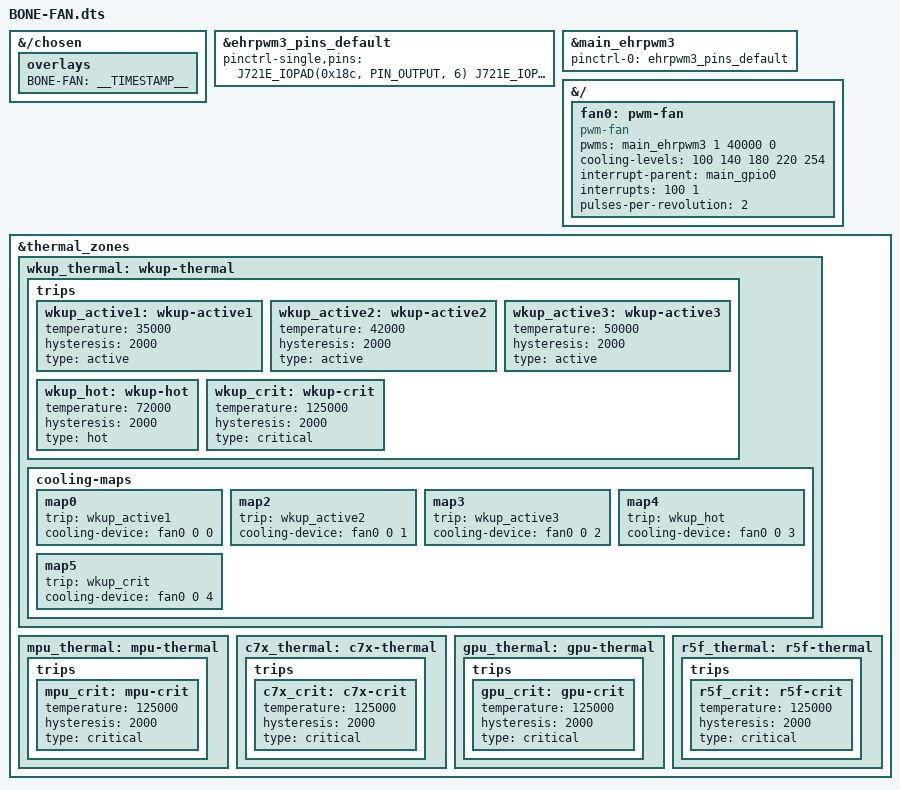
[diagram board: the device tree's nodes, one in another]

// SPDX-License-Identifier: GPL-2.0
/*
 */

/dts-v1/;
/plugin/;

#include <dt-bindings/pinctrl/k3.h>

/*
 * Helper to show loaded overlays under: /proc/device-tree/chosen/overlays/
 */
&{/chosen} {
	overlays {
		BONE-FAN = __TIMESTAMP__;
	};
};

&ehrpwm3_pins_default{
	pinctrl-single,pins = <
		J721E_IOPAD(0x18c, PIN_OUTPUT, 6) /* (V23) RGMII6_RX_CTL.EHRPWM3_A */
		J721E_IOPAD(0x190, PIN_OUTPUT, 6) /* (W23) RGMII6_TD3.EHRPWM3_B */
		J721E_IOPAD(0x194, PIN_INPUT_PULLUP, 7) /* (W28) RGMII6_TD2.GPIO0_100 */
	>;
};

&main_ehrpwm3 {
	pinctrl-names = "default";
	pinctrl-0 = <&ehrpwm3_pins_default>;
	status = "okay";
};

&{/} {
	fan0: pwm-fan {
		compatible = "pwm-fan";
		#cooling-cells = <2>;
		pwms = <&main_ehrpwm3 1 40000 0>;
		cooling-levels = <100 140 180 220 254>;
		interrupt-parent = <&main_gpio0>;
		interrupts = <100 1>;
		pulses-per-revolution = <2>;
	};
};

&thermal_zones{
	wkup_thermal: wkup-thermal {
		trips {
			wkup_active1: wkup-active1 {
				temperature = <35000>; /* milliCelsius */
				hysteresis = <2000>; /* milliCelsius */
				type = "active";
			};
			wkup_active2: wkup-active2 {
				temperature = <42000>; /* milliCelsius */
				hysteresis = <2000>; /* milliCelsius */
				type = "active";
			};
			wkup_active3: wkup-active3 {
				temperature = <50000>; /* milliCelsius */
				hysteresis = <2000>; /* milliCelsius */
				type = "active";
			};
			wkup_hot: wkup-hot {
				temperature = <72000>; /* milliCelsius */
				hysteresis = <2000>; /* milliCelsius */
				type = "hot";
			};
			wkup_crit: wkup-crit {
				temperature = <125000>; /* milliCelsius */
				hysteresis = <2000>; /* milliCelsius */
				type = "critical";
			};
		};

		cooling-maps {
			map0 {
				trip = <&wkup_active1>;
				cooling-device = <&fan0 0 0>;
			};
			map2 {
				trip = <&wkup_active2>;
				cooling-device = <&fan0 0 1>;
			};
			map3 {
				trip = <&wkup_active3>;
				cooling-device = <&fan0 0 2>;
			};
			map4 {
				trip = <&wkup_hot>;
				cooling-device = <&fan0 0 3>;
			};
			map5 {
				trip = <&wkup_crit>;
				cooling-device = <&fan0 0 4>;
			};
		};
	};

	mpu_thermal: mpu-thermal {
		trips {
			mpu_crit: mpu-crit {
				temperature = <125000>; /* milliCelsius */
				hysteresis = <2000>; /* milliCelsius */
				type = "critical";
			};
		};
	};

	c7x_thermal: c7x-thermal {
		trips {
			c7x_crit: c7x-crit {
				temperature = <125000>; /* milliCelsius */
				hysteresis = <2000>; /* milliCelsius */
				type = "critical";
			};
		};
	};

	gpu_thermal: gpu-thermal {
		trips {
			gpu_crit: gpu-crit {
				temperature = <125000>; /* milliCelsius */
				hysteresis = <2000>; /* milliCelsius */
				type = "critical";
			};
		};
	};

	r5f_thermal: r5f-thermal {
		trips {
			r5f_crit: r5f-crit {
				temperature = <125000>; /* milliCelsius */
				hysteresis = <2000>; /* milliCelsius */
				type = "critical";
			};
		};
	};
};
